# flctl register map
Vendor: Texas Instruments
Peripheral module from a debugger description file (folder MSP432).
Registers are 32-bit, read-write, no defined reset value unless marked. A register's access mark holds for its fields unless they carry their own. Offsets are as the file gives them; lines under a group give offsets from that group; [hi:lo] are bit positions; {n}, {i} and the like mark numbered series; 'fields as' and 'values as' point back to an identical list; <NAME> marks a mode.

## FLCTL
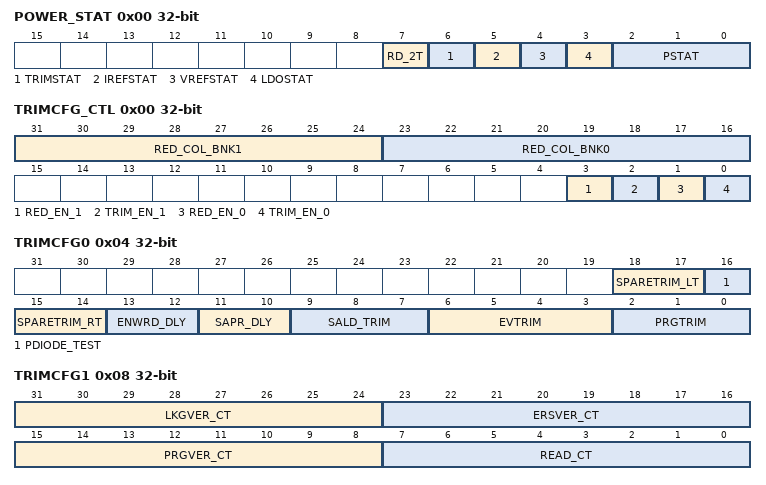
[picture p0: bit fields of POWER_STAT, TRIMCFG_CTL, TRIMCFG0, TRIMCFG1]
0x00 POWER_STAT — Power Status Register
  [7] RD_2T — Indicates if Flash is being accessed in 2T mode
    0=RD_2T__0 (Flash reads are in 1T mode); 1=RD_2T__1 (Flash reads are in 2T mode)
  [6] TRIMSTAT — PSS trim done status
    0=TRIMSTAT__0 (PSS trim not complete); 1=TRIMSTAT__1 (PSS trim complete)
  [5] IREFSTAT — PSS IREF stable status
    0=IREFSTAT__0 (IREF not stable); 1=IREFSTAT__1 (IREF stable)
  [4] VREFSTAT — PSS VREF stable status
    0=VREFSTAT__0 (Flash LDO not stable); 1=VREFSTAT__1 (Flash LDO stable)
  [3] LDOSTAT — PSS FLDO GOOD status
    0=LDOSTAT__0 (FLDO not GOOD); 1=LDOSTAT__1 (FLDO GOOD)
  [2:0] PSTAT — Flash power status
    0=PSTAT__0 (Flash IP in power-down mode); 1=PSTAT__1 (Flash IP Vdd domain power-up in progress); 2=PSTAT__2 (PSS LDO_GOOD, IREF_OK and VREF_OK check in progress); 3=PSTAT__3 (Flash IP SAFE_LV check in progress); 4=PSTAT__4 (Flash IP Active); 5=PSTAT__5 (Flash IP Active in Low-Frequency Active and Low-Frequency LPM0); 6=PSTAT__6 (Flash IP in Standby mode); 7=PSTAT__7 (Flash IP in Current mirror boost state)
0x00 TRIMCFG_CTL — Trim Configuration Control Register
  [31:24] RED_COL_BNK1 — Controls the REDUNDANCY_COLUMN bits of Bank1 (bits[7:0] of trim
  [23:16] RED_COL_BNK0 — Controls the REDUNDANCY_COLUMN bits of the TRIMCFG bus for Bank
  [3] RED_EN_1 — Controls the REDUNDANCY_EN bit of the TRIMCFG bus for Bank1 (bi
  [2] TRIM_EN_1 — Controls the TRIMCFG_EN input of Bank1
  [1] RED_EN_0 — Controls the REDUNDANCY_EN bit of the TRIMCFG bus for Bank0 (bi
  [0] TRIM_EN_0 — Controls the TRIMCFG_EN input of Bank0
0x04 TRIMCFG0 — Trim Configuration 0 Register
  [18:17] SPARETRIM_LT — Controls the Unused trim bits on the left side of the IPs (conn
  [16] PDIODE_TEST — Controls the 0
  [15:14] SPARETRIM_RT — Controls the Unused trim bits on the right side of the IPs (con
  [13:12] ENWRD_DLY — Controls the Enable Wordline delay bits of the IPs (connected t
  [11:10] SAPR_DLY — Controls the Sense Amp Precharge delay bits of the IPs (connect
  [9:7] SALD_TRIM — Controls the Sense Amp Latch Delay Trim bits of the IPs (connec
  [6:3] EVTRIM — Controls the EV Temp Controlled Current Trim bits of the IPs (c
  [2:0] PRGTRIM — Controls the Program Current Trim bits of the IPs (connected to
0x08 TRIMCFG1 — Trim Configuration 1 Register
  [31:24] LKGVER_CT — Controls the LKGVER_CT bits of the IPs (connected to bits [40:3
  [23:16] ERSVER_CT — Controls the ERSVER_CT bits of the IPs (connected to bits [32:2
  [15:8] PRGVER_CT — Controls the PRGVER_CT bits of the IPs (connected to bits [24:1
  [7:0] READ_CT — Controls the READ_CT bits of the IPs (connected to bits [16:9]
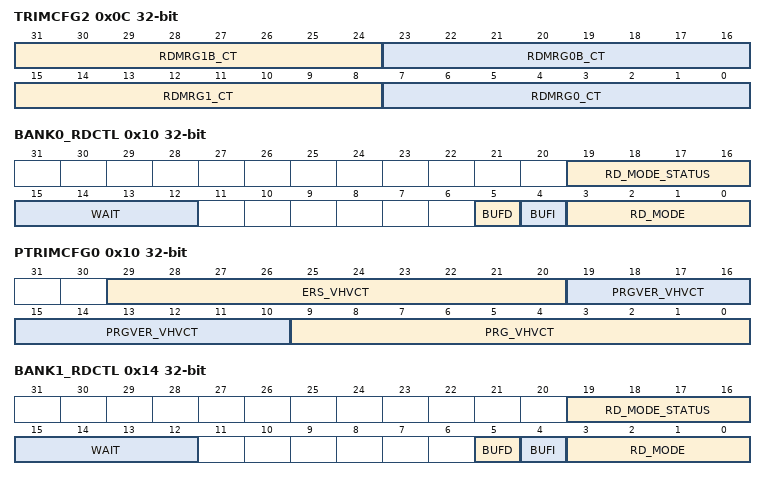
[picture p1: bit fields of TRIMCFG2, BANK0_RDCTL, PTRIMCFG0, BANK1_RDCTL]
0x0C TRIMCFG2 — Trim Configuration 2 Register
  [31:24] RDMRG1B_CT — Controls the RDMRG1B_CT bits of the IPs (connected to bits [72:
  [23:16] RDMRG0B_CT — Controls the RDMRG0B_CT bits of the IPs (connected to bits [64:
  [15:8] RDMRG1_CT — Controls the RDMRG1_CT bits of the IPs (connected to bits [56:4
  [7:0] RDMRG0_CT — Controls the RDMRG0_CT bits of the IPs (connected to bits [48:4
0x10 BANK0_RDCTL — Bank0 Read Control Register
  [19:16] RD_MODE_STATUS — Reflects the current Read Mode of the Bank 1001 = Read Margin 0
    0=RD_MODE_STATUS__0 (Normal read mode); 1=RD_MODE_STATUS__1 (Read Margin 0); 2=RD_MODE_STATUS__2 (Read Margin 1); 3=RD_MODE_STATUS__3 (Program Verify); 4=RD_MODE_STATUS__4 (Erase Verify); 5=RD_MODE_STATUS__5 (Leakage Verify); 9=RD_MODE_STATUS__9 (Read Margin 0B); 10=RD_MODE_STATUS__10 (Read Margin 1B)
  [15:12] WAIT — Defines the number of wait states required for a read operation
    {v}=WAIT__{v} ({v} wait states) (v=0..9); {v}=WAIT__{v+6} ({v} wait states) (v=10..15)
  [5] BUFD — Enables read buffering feature for data reads to this Bank
  [4] BUFI — Enables read buffering feature for instruction fetches to this
  [3:0] RD_MODE — Flash read mode control setting for Bank 0
    0=RD_MODE__0 (Normal read mode); 1=RD_MODE__1 (Read Margin 0); 2=RD_MODE__2 (Read Margin 1); 3=RD_MODE__3 (Program Verify); 4=RD_MODE__4 (Erase Verify); 5=RD_MODE__5 (Leakage Verify); 9=RD_MODE__9 (Read Margin 0B); 10=RD_MODE__10 (Read Margin 1B)
0x10 PTRIMCFG0 — Flash Pump Trim Configuration 0 Register
  [29:20] ERS_VHVCT — Controls the VHV_CT bits of the Pump when IP is in Erase mode
  [19:10] PRGVER_VHVCT — Controls the VHV_CT bits of the Pump when IP is in Program Veri
  [9:0] PRG_VHVCT — Controls the VHV_CT bits of the Pump when IP is in program mode
0x14 BANK1_RDCTL — Bank1 Read Control Register
  fields as BANK0_RDCTL
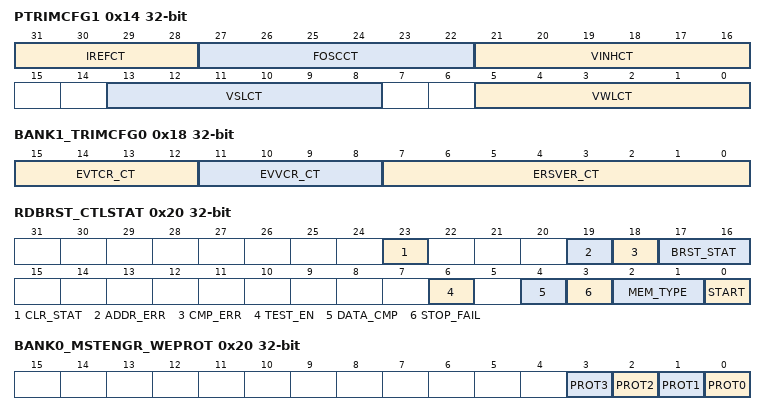
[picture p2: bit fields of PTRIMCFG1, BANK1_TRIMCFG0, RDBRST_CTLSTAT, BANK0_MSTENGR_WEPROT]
0x14 PTRIMCFG1 — Flash Pump Trim Configuration 1 Register
  [31:28] IREFCT — Controls the IREFCT bits of the Pump
  [27:22] FOSCCT — Controls the FOSCT bits of the Pump
  [21:16] VINHCT — Controls the VINHCT bits of the Pump
  [13:8] VSLCT — Controls the VSLCT bits of the Pump
  [5:0] VWLCT — Controls the VWLCT bits of the Pump
0x18 BANK1_TRIMCFG0 — Bank1 Trim Configuration 0 Register
  [15:12] EVTCR_CT — Controls Temperature controlled current reference trim (erase v
  [11:8] EVVCR_CT — Controls Voltage controlled current reference trim (erase verif
  [7:0] ERSVER_CT — Controls Erase Verify Reference Current Trim Value for Bank-1 (
0x20 RDBRST_CTLSTAT — Read Burst/Compare Control and Status Register
  [23] CLR_STAT — Write '1' to clear status bits 19-16 of this register
  [19] ADDR_ERR — If 1, indicates that Burst/Compare Operation was terminated due
  [18] CMP_ERR — if 1, indicates that the Burst/Compare Operation encountered at
  [17:16] BRST_STAT — Status of Burst/Compare operation
    0=BRST_STAT__0 (Idle); 1=BRST_STAT__1 (Burst/Compare START bit written, but operation pending); 2=BRST_STAT__2 (Burst/Compare in progress); 3=BRST_STAT__3 (Burst complete (status of completed burst remains in this state)
  [6] TEST_EN — When set to 1, enables comparison against test data compare reg
  [4] DATA_CMP — Data pattern used for comparison against memory read data
    0=DATA_CMP__0 (0000_0000_0000_0000_0000_0000_0000_0000); 1=DATA_CMP__1 (FFFF_FFFF_FFFF_FFFF_FFFF_FFFF_FFFF_FFFF)
  [3] STOP_FAIL — If set to 1, causes burst/compare operation to terminate on fir
  [2:1] MEM_TYPE — Type of memory that burst is carried out on
    0=MEM_TYPE__0 (Main Memory); 1=MEM_TYPE__1 (Information Memory); 2=MEM_TYPE__2 (Reserved); 3=MEM_TYPE__3 (Engineering Memory)
  [0] START — Write 1 triggers start of burst/compare operation
0x20 BANK0_MSTENGR_WEPROT — Bank0 Engineering Memory Master Write/Erase Protection Register
  [n] PROT{n} (n=0..3) — If set to 1, protects Sector {n} from program or erase operations
0x24 RDBRST_STARTADDR — Read Burst/Compare Start Address Register
  [20:0] START_ADDRESS — Start Address of Burst Operation
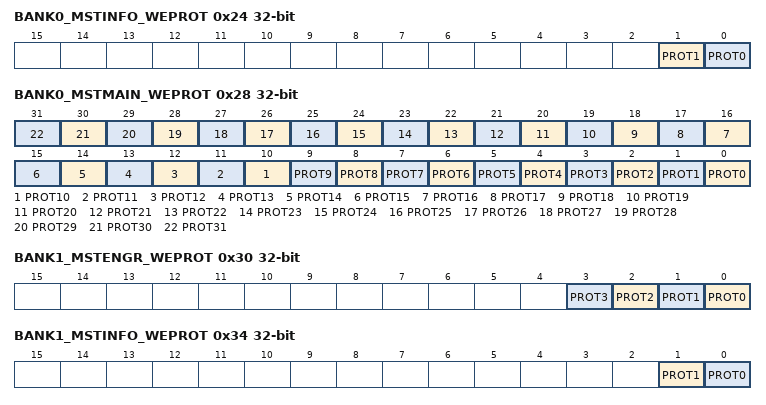
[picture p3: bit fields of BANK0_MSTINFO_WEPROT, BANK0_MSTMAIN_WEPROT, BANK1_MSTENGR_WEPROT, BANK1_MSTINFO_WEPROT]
0x24 BANK0_MSTINFO_WEPROT — Bank0 Information Memory Master Write/Erase Protection Register
  [1] PROT1 — If set to 1, protects Sector 1 from program or erase operations
  [0] PROT0 — If set to 1, protects Sector 0 from program or erase operations
0x28 RDBRST_LEN — Read Burst/Compare Length Register
  [20:0] BURST_LENGTH — Length of Burst Operation (in bytes)
0x28 BANK0_MSTMAIN_WEPROT — Bank0 Main Memory Master Write/Erase Protection Register
  [n] PROT{n} (n=0..31) — If set to 1, protects Sector {n} from program or erase operations
0x30 BANK1_MSTENGR_WEPROT — Bank1 Engineering Memory Master Write/Erase Protection Register
  fields as BANK0_MSTENGR_WEPROT
0x34 BANK1_MSTINFO_WEPROT — Bank1 Information Memory Master Write/Erase Protection Register
  fields as BANK0_MSTINFO_WEPROT
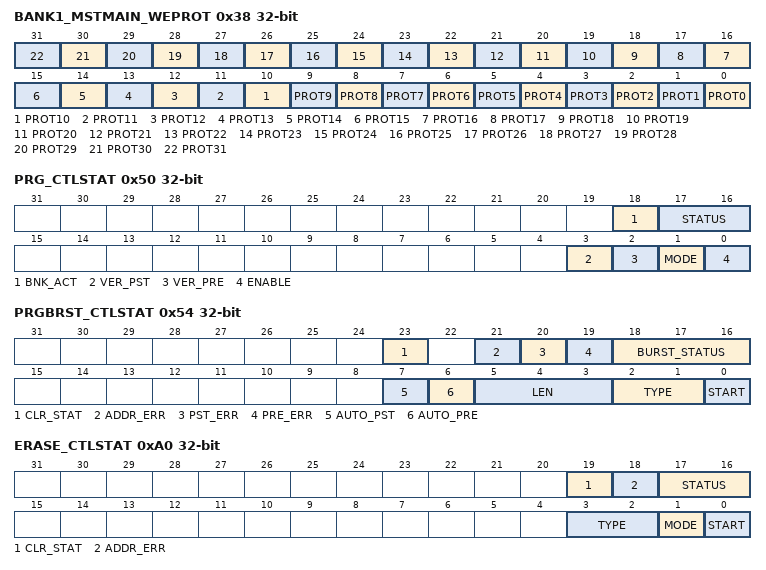
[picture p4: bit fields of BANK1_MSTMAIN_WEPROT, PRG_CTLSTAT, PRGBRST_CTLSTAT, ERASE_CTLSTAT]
0x38 BANK1_MSTMAIN_WEPROT — Bank1 Main Memory Master Write/Erase Protection Register
  fields as BANK0_MSTMAIN_WEPROT
0x3C RDBRST_FAILADDR — Read Burst/Compare Fail Address Register
  [20:0] FAIL_ADDRESS — Reflects address of last failed compare
0x40 RDBRST_FAILCNT — Read Burst/Compare Fail Count Register
  [16:0] FAIL_COUNT — Reflects number of failures encountered in burst operation.
0x50 PRG_CTLSTAT — Program Control and Status Register
  [18] BNK_ACT — Reflects which bank is currently undergoing a program operation
    0=BNK_ACT__0 (Word in Bank0 being programmed); 1=BNK_ACT__1 (Word in Bank1 being programmed)
  [17:16] STATUS — Reflects the status of program operations in the Flash memory
    0=STATUS__0 (Idle (no program operation currently active)); 1=STATUS__1 (Single word program operation triggered, but pending); 2=STATUS__2 (Single word program in progress); 3=STATUS__3 (Reserved (Idle))
  [3] VER_PST — Controls automatic post program verify operations
    0=VER_PST__0 (No post program verification); 1=VER_PST__1 (Post verify feature automatically invoked for each write operat)
  [2] VER_PRE — Controls automatic pre program verify operations
    0=VER_PRE__0 (No pre program verification); 1=VER_PRE__1 (Pre verify feature automatically invoked for each write operati)
  [1] MODE — Controls write mode selected by application
    0=MODE__0 (Write immediate mode); 1=MODE__1 (Full word write mode)
  [0] ENABLE — Master control for all word program operations
    0=ENABLE__0 (Word program operation disabled); 1=ENABLE__1 (Word program operation enabled)
0x54 PRGBRST_CTLSTAT — Program Burst Control and Status Register
  [23] CLR_STAT — Write '1' to clear status bits 21-16 of this register Write '0
  [21] ADDR_ERR — If 1, indicates that Burst Operation was terminated due to atte
  [20] PST_ERR — if 1, indicates that the Burst Operation encountered postprogra
  [19] PRE_ERR — If 1, indicates that Burst Operation encountered preprogram aut
  [18:16] BURST_STATUS — At any point in time, it reflects the status of a Burst Operati
    0=BURST_STATUS__0 (Idle (Burst not active)); 1=BURST_STATUS__1 (Burst program started but pending); 2=BURST_STATUS__2 (Burst active, with 1st 128 bit word being written into Flash); 3=BURST_STATUS__3 (Burst active, with 2nd 128 bit word being written into Flash); 4=BURST_STATUS__4 (Burst active, with 3rd 128 bit word being written into Flash); 5=BURST_STATUS__5 (Burst active, with 4th 128 bit word being written into Flash); 6=BURST_STATUS__6 (Reserved (Idle)); 7=BURST_STATUS__7 (Burst Complete (status of completed burst remains in this state)
  [7] AUTO_PST — Controls the Auto-Verify operation after the Burst Program
    0=AUTO_PST__0 (No program verify operations carried out); 1=AUTO_PST__1 (Causes an automatic Burst Program Verify before the Burst Progr)
  [6] AUTO_PRE — Controls the Auto-Verify operation before the Burst Program
    0=AUTO_PRE__0 (No program verify operations carried out); 1=AUTO_PRE__1 (Causes an automatic Burst Program Verify after the Burst Progra)
  [5:3] LEN — Length of burst (in 128 bit granularity)
    0=LEN__0 (No burst operation); 1=LEN__1 (1 word burst of 128 bits, starting with address in the FLCTL_PR); 2=LEN__2 (2*128 bits burst write, starting with address in the FLCTL_PRGB); 3=LEN__3 (3*128 bits burst write, starting with address in the FLCTL_PRGB); 4=LEN__4 (4*128 bits burst write, starting with address in the FLCTL_PRGB)
  [2:1] TYPE — Type of memory that burst program is carried out on
    0=TYPE__0 (Main Memory); 1=TYPE__1 (Information Memory); 2=TYPE__2 (Reserved); 3=TYPE__3 (Engineering Memory)
  [0] START — Write 1 triggers start of burst program operation
0x58 PRGBRST_STARTADDR — Program Burst Start Address Register
  [21:0] START_ADDRESS — Start Address of Program Burst Operation
{0x60+0x10*i} PRGBRST_DATA{i}_0 (i=0..3) — Program Burst Data{i} Register0
  [31:0] DATAIN — Program Burst 128 bit Data Word {i} (bits (32*(x+1)-1) downto 32*
{0x64+0x10*i} PRGBRST_DATA{i}_1 (i=0..3) — Program Burst Data{i} Register1
  fields as PRGBRST_DATA0_0
{0x68+0x10*i} PRGBRST_DATA{i}_2 (i=0..3) — Program Burst Data{i} Register2
  fields as PRGBRST_DATA0_0
{0x6C+0x10*i} PRGBRST_DATA{i}_3 (i=0..3) — Program Burst Data{i} Register3
  fields as PRGBRST_DATA0_0
0xA0 ERASE_CTLSTAT — Erase Control and Status Register
  [19] CLR_STAT — Write '1' to clear status bits 18-16 of this register Write '0
  [18] ADDR_ERR — If 1, indicates that Erase Operation was terminated due to atte
  [17:16] STATUS — Reflects the status of erase operations in the Flash memory
    0=STATUS__0 (Idle (no program operation currently active)); 1=STATUS__1 (Erase operation triggered to START but pending); 2=STATUS__2 (Erase operation in progress); 3=STATUS__3 (Erase operation completed (status of completed erase remains in)
  [3:2] TYPE — Type of memory that erase operation is carried out on (don't ca
    values as PRGBRST_CTLSTAT.TYPE
  [1] MODE — Controls erase mode selected by application
    0=MODE__0 (Sector Erase (controlled by FLTCTL_ERASE_SECTADDR)); 1=MODE__1 (Mass Erase (includes all Main and Information memory sectors th)
  [0] START — Write 1 triggers start of Erase operation
0xA4 ERASE_SECTADDR — Erase Sector Address Register
  [21:0] SECT_ADDRESS — Address of Sector being Erased
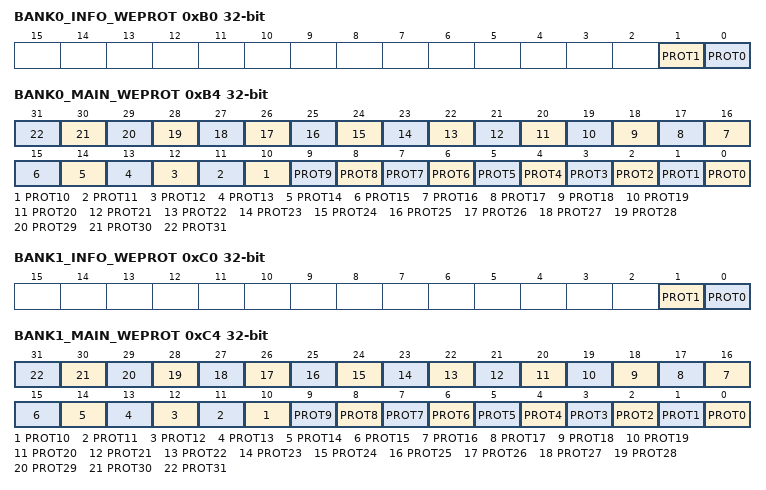
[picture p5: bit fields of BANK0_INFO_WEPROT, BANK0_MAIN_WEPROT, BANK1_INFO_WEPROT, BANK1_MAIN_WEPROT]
0xB0 BANK0_INFO_WEPROT — Information Memory Bank0 Write/Erase Protection Register
  fields as BANK0_MSTINFO_WEPROT
0xB4 BANK0_MAIN_WEPROT — Main Memory Bank0 Write/Erase Protection Register
  fields as BANK0_MSTMAIN_WEPROT
0xC0 BANK1_INFO_WEPROT — Information Memory Bank1 Write/Erase Protection Register
  fields as BANK0_MSTINFO_WEPROT
0xC4 BANK1_MAIN_WEPROT — Main Memory Bank1 Write/Erase Protection Register
  fields as BANK0_MSTMAIN_WEPROT
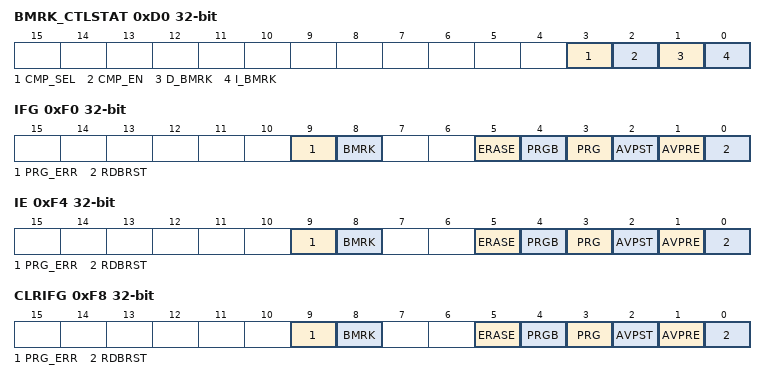
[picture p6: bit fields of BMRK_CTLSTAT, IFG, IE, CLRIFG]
0xD0 BMRK_CTLSTAT — Benchmark Control and Status Register
  [3] CMP_SEL — Selects which benchmark register should be compared against the
    0=CMP_SEL__0 (Compares the Instruction Benchmark Register against the thresho); 1=CMP_SEL__1 (Compares the Data Benchmark Register against the threshold value)
  [2] CMP_EN — When 1, enables comparison of the Instruction or Data Benchmark
  [1] D_BMRK — When 1, increments the Data Benchmark count register on each da
  [0] I_BMRK — When 1, increments the Instruction Benchmark count register on
0xD4 BMRK_IFETCH — Benchmark Instruction Fetch Count Register
  [31:0] COUNT — Reflects the number of Instruction Fetches to the Flash (increm
0xD8 BMRK_DREAD — Benchmark Data Read Count Register
  [31:0] COUNT — Reflects the number of Data Read operations to the Flash (incre
0xDC BMRK_CMP — Benchmark Count Compare Register
  [31:0] COUNT — Reflects the threshold value that is compared against either th
0xF0 IFG — Interrupt Flag Register
  [9] PRG_ERR — If set to 1, indicates a word composition error in full word wr
  [8] BMRK — If set to 1, indicates that a Benchmark Compare match occurred
  [5] ERASE — If set to 1, indicates that the Erase operation is complete
  [4] PRGB — If set to 1, indicates that the configured Burst Program operat
  [3] PRG — If set to 1, indicates that a word Program operation is complete
  [2] AVPST — If set to 1, indicates that the post-program verify operation h
  [1] AVPRE — If set to 1, indicates that the pre-program verify operation ha
  [0] RDBRST — If set to 1, indicates that the Read Burst/Compare operation is
0xF4 IE — Interrupt Enable Register
  [9] PRG_ERR — If set to 1, enables the Controller to generate an interrupt ba
  [8] BMRK — If set to 1, enables the Controller to generate an interrupt ba
  [5] ERASE — If set to 1, enables the Controller to generate an interrupt ba
  [4] PRGB — If set to 1, enables the Controller to generate an interrupt ba
  [3] PRG — If set to 1, enables the Controller to generate an interrupt ba
  [2] AVPST — If set to 1, enables the Controller to generate an interrupt ba
  [1] AVPRE — If set to 1, enables the Controller to generate an interrupt ba
  [0] RDBRST — If set to 1, enables the Controller to generate an interrupt ba
0xF8 CLRIFG — Clear Interrupt Flag Register
  [9] PRG_ERR — Write 1 clears the corresponding interrupt flag bit in the FLCT
  [8] BMRK — Write 1 clears the corresponding interrupt flag bit in the FLCT
  [5] ERASE — Write 1 clears the corresponding interrupt flag bit in the FLCT
  [4] PRGB — Write 1 clears the corresponding interrupt flag bit in the FLCT
  [3] PRG — Write 1 clears the corresponding interrupt flag bit in the FLCT
  [2] AVPST — Write 1 clears the corresponding interrupt flag bit in the FLCT
  [1] AVPRE — Write 1 clears the corresponding interrupt flag bit in the FLCT
  [0] RDBRST — Write 1 clears the corresponding interrupt flag bit in the FLCT
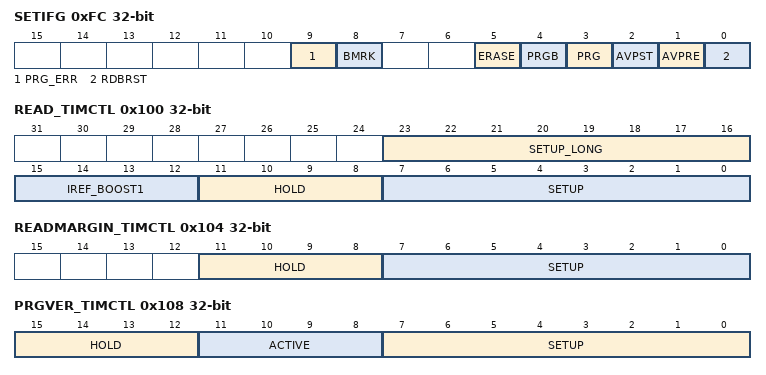
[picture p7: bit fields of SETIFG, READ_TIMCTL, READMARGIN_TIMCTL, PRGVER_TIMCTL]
0xFC SETIFG — Set Interrupt Flag Register
  fields as CLRIFG
0x100 READ_TIMCTL — Read Timing Control Register
  [23:16] SETUP_LONG — Configures the length of the Setup time into read mode when the
  [15:12] IREF_BOOST1 — Configures the length of the IREF_BOOST1 signal of the IP
  [11:8] HOLD — Configures the length of the Hold phase for this operation
  [7:0] SETUP — Configures the length of the Setup phase for this operation
0x104 READMARGIN_TIMCTL — Read Margin Timing Control Register
  [11:8] HOLD — Configures the length of the Hold phase for this operation
  [7:0] SETUP — Configures the length of the Setup phase for this operation
0x108 PRGVER_TIMCTL — Program Verify Timing Control Register
  [15:12] HOLD — Configures the length of the Hold phase for this operation
  [11:8] ACTIVE — Configures the length of the Active phase for this operation
  [7:0] SETUP — Configures the length of the Setup phase for this operation
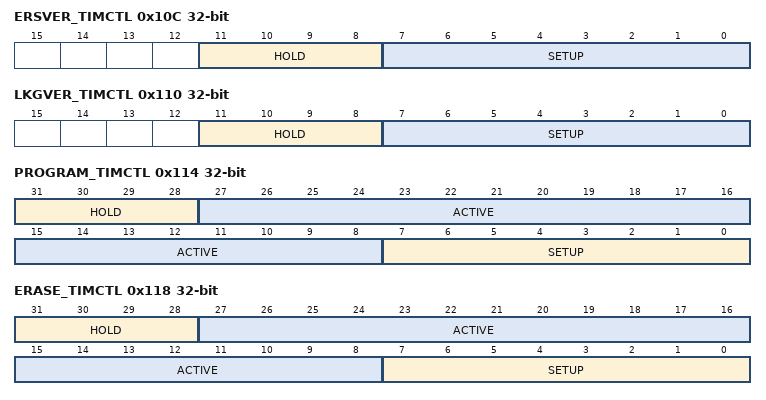
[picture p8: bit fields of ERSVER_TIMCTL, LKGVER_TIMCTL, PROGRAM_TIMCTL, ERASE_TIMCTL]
0x10C ERSVER_TIMCTL — Erase Verify Timing Control Register
  fields as READMARGIN_TIMCTL
0x110 LKGVER_TIMCTL — Leakage Verify Timing Control Register
  fields as READMARGIN_TIMCTL
0x114 PROGRAM_TIMCTL — Program Timing Control Register
  [31:28] HOLD — Configures the length of the Hold phase for this operation
  [27:8] ACTIVE — Configures the length of the Active phase for this operation
  [7:0] SETUP — Configures the length of the Setup phase for this operation
0x118 ERASE_TIMCTL — Erase Timing Control Register
  fields as PROGRAM_TIMCTL
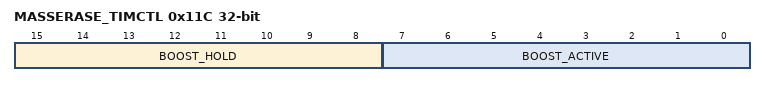
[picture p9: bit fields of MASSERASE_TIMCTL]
0x11C MASSERASE_TIMCTL — Mass Erase Timing Control Register
  [15:8] BOOST_HOLD — Configures the length for which Flash deactivates the LDO Boost
  [7:0] BOOST_ACTIVE — Configures the length of the time for which LDO Boost Signal is
0x120 BURSTPRG_TIMCTL — Burst Program Timing Control Register
  [27:8] ACTIVE — Configures the length of the Active phase for this operation
